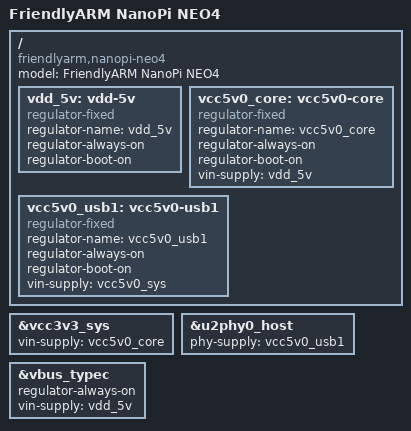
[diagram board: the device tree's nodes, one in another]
// SPDX-License-Identifier: (GPL-2.0+ OR MIT)
/*
 * Copyright (C) 2019 Amarula Solutions B.V.
 * Author: Jagan Teki <jagan@amarulasolutions.com>
 */

/dts-v1/;

#include "rk3399-nanopi4.dtsi"

/ {
	model = "FriendlyARM NanoPi NEO4";
	compatible = "friendlyarm,nanopi-neo4", "rockchip,rk3399";

	vdd_5v: vdd-5v {
		compatible = "regulator-fixed";
		regulator-name = "vdd_5v";
		regulator-always-on;
		regulator-boot-on;
	};

	vcc5v0_core: vcc5v0-core {
		compatible = "regulator-fixed";
		regulator-name = "vcc5v0_core";
		regulator-always-on;
		regulator-boot-on;
		vin-supply = <&vdd_5v>;
	};

	vcc5v0_usb1: vcc5v0-usb1 {
		compatible = "regulator-fixed";
		regulator-name = "vcc5v0_usb1";
		regulator-always-on;
		regulator-boot-on;
		vin-supply = <&vcc5v0_sys>;
	};
};

&vcc3v3_sys {
	vin-supply = <&vcc5v0_core>;
};

&u2phy0_host {
	phy-supply = <&vcc5v0_usb1>;
};

&vbus_typec {
	regulator-always-on;
	vin-supply = <&vdd_5v>;
};
